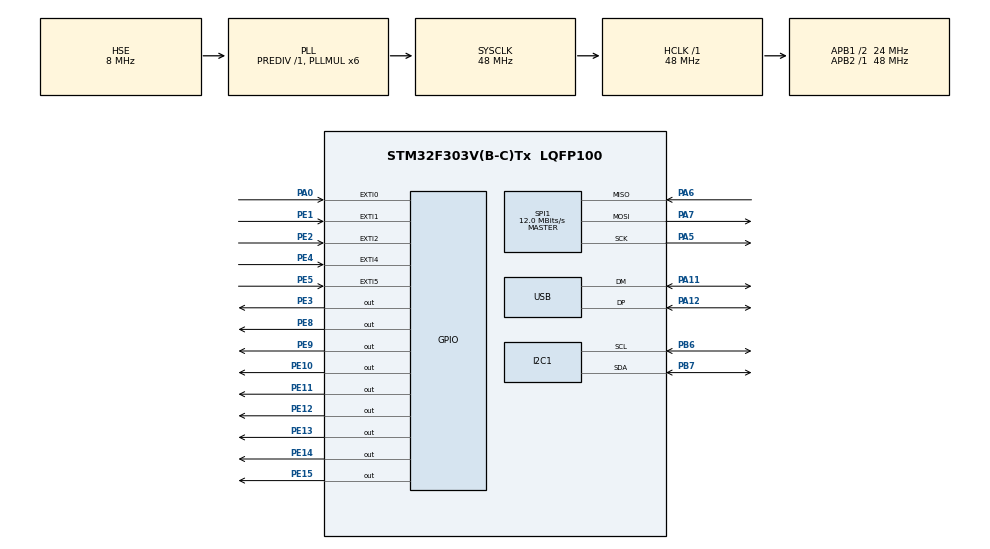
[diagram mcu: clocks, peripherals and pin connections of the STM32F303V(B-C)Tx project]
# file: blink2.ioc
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FREERTOS.Tasks01=defaultTask,0,128,StartDefaultTask,Default
FREERTOS.configTOTAL_HEAP_SIZE=4096
I2C1.Timing-I2C=0x2000090E
Mcu.Family=STM32F3
Mcu.Name=STM32F303V(B-C)Tx
Mcu.Package=LQFP100
NVIC.EXTI0_IRQn=true\:5\:0\:false\:false\:true\:true
NVIC.PriorityGroup=NVIC_PRIORITYGROUP_4
PA0.GPIO_ModeDefaultEXTI=GPIO_MODE_IT_RISING
PA0.GPIO_PuPd=GPIO_NOPULL
PA0.Signal=GPXTI0
PA11.GPIO_Mode=GPIO_MODE_AF_PP
PA11.GPIO_PuPd=GPIO_NOPULL
PA11.GPIO_Speed=GPIO_SPEED_FREQ_HIGH
PA11.Mode=Device
PA11.Signal=USB_DM
PA12.GPIO_Mode=GPIO_MODE_AF_PP
PA12.GPIO_PuPd=GPIO_NOPULL
PA12.GPIO_Speed=GPIO_SPEED_FREQ_HIGH
PA12.Mode=Device
PA12.Signal=USB_DP
PA13.Mode=Serial_Wire
PA13.Signal=SYS_JTMS-SWDIO
PA14.Mode=Serial_Wire
PA14.Signal=SYS_JTCK-SWCLK
PA5.GPIO_Mode=GPIO_MODE_AF_PP
PA5.GPIO_PuPd=GPIO_NOPULL
PA5.GPIO_Speed=GPIO_SPEED_FREQ_HIGH
PA5.Mode=Full_Duplex_Master
PA5.Signal=SPI1_SCK
PA6.GPIO_Mode=GPIO_MODE_AF_PP
PA6.GPIO_PuPd=GPIO_NOPULL
PA6.GPIO_Speed=GPIO_SPEED_FREQ_HIGH
PA6.Mode=Full_Duplex_Master
PA6.Signal=SPI1_MISO
PA7.GPIO_Mode=GPIO_MODE_AF_PP
PA7.GPIO_PuPd=GPIO_NOPULL
PA7.GPIO_Speed=GPIO_SPEED_FREQ_HIGH
PA7.Mode=Full_Duplex_Master
PA7.Signal=SPI1_MOSI
PB3.Signal=SYS_JTDO-TRACESWO
PB6.GPIO_FM6=__NULL
PB6.GPIO_Mode=GPIO_MODE_AF_OD
PB6.GPIO_PuPdOD=GPIO_PULLUP
PB6.GPIO_Speed=GPIO_SPEED_FREQ_HIGH
PB6.Mode=I2C
PB6.Signal=I2C1_SCL
PB7.GPIO_FM7=__NULL
PB7.GPIO_Mode=GPIO_MODE_AF_OD
PB7.GPIO_PuPdOD=GPIO_PULLUP
PB7.GPIO_Speed=GPIO_SPEED_FREQ_HIGH
PB7.Mode=I2C
PB7.Signal=I2C1_SDA
PC14-OSC32_IN.Signal=RCC_OSC32_IN
PC15-OSC32_OUT.Signal=RCC_OSC32_OUT
PE1.GPIO_ModeDefaultEXTI=GPIO_MODE_IT_RISING
PE1.GPIO_PuPd=GPIO_NOPULL
PE1.Signal=GPXTI1
PE10.GPIO_ModeDefaultOutputPP=GPIO_MODE_OUTPUT_PP
PE10.GPIO_PuPd=GPIO_NOPULL
PE10.GPIO_Speed=GPIO_SPEED_FREQ_LOW
PE10.PinState=GPIO_PIN_RESET
PE10.Signal=GPIO_Output
PE11.GPIO_ModeDefaultOutputPP=GPIO_MODE_OUTPUT_PP
PE11.GPIO_PuPd=GPIO_NOPULL
PE11.GPIO_Speed=GPIO_SPEED_FREQ_LOW
PE11.PinState=GPIO_PIN_RESET
PE11.Signal=GPIO_Output
PE12.GPIO_ModeDefaultOutputPP=GPIO_MODE_OUTPUT_PP
PE12.GPIO_PuPd=GPIO_NOPULL
PE12.GPIO_Speed=GPIO_SPEED_FREQ_LOW
PE12.PinState=GPIO_PIN_RESET
PE12.Signal=GPIO_Output
PE13.GPIO_ModeDefaultOutputPP=GPIO_MODE_OUTPUT_PP
PE13.GPIO_PuPd=GPIO_NOPULL
PE13.GPIO_Speed=GPIO_SPEED_FREQ_LOW
PE13.PinState=GPIO_PIN_RESET
PE13.Signal=GPIO_Output
PE14.GPIO_ModeDefaultOutputPP=GPIO_MODE_OUTPUT_PP
PE14.GPIO_PuPd=GPIO_NOPULL
PE14.GPIO_Speed=GPIO_SPEED_FREQ_LOW
PE14.PinState=GPIO_PIN_RESET
PE14.Signal=GPIO_Output
PE15.GPIO_ModeDefaultOutputPP=GPIO_MODE_OUTPUT_PP
PE15.GPIO_PuPd=GPIO_NOPULL
PE15.GPIO_Speed=GPIO_SPEED_FREQ_LOW
PE15.PinState=GPIO_PIN_RESET
PE15.Signal=GPIO_Output
PE2.GPIO_ModeDefaultEXTI=GPIO_MODE_IT_RISING
PE2.GPIO_PuPd=GPIO_NOPULL
PE2.Signal=GPXTI2
PE3.GPIO_ModeDefaultOutputPP=GPIO_MODE_OUTPUT_PP
PE3.GPIO_PuPd=GPIO_NOPULL
PE3.GPIO_Speed=GPIO_SPEED_FREQ_LOW
PE3.PinState=GPIO_PIN_RESET
PE3.Signal=GPIO_Output
PE4.GPIO_ModeDefaultEXTI=GPIO_MODE_IT_RISING
PE4.GPIO_PuPd=GPIO_NOPULL
PE4.Signal=GPXTI4
PE5.GPIO_ModeDefaultEXTI=GPIO_MODE_IT_RISING
PE5.GPIO_PuPd=GPIO_NOPULL
PE5.Signal=GPXTI5
PE8.GPIO_ModeDefaultOutputPP=GPIO_MODE_OUTPUT_PP
PE8.GPIO_PuPd=GPIO_NOPULL
PE8.GPIO_Speed=GPIO_SPEED_FREQ_LOW
PE8.PinState=GPIO_PIN_RESET
PE8.Signal=GPIO_Output
PE9.GPIO_ModeDefaultOutputPP=GPIO_MODE_OUTPUT_PP
PE9.GPIO_PuPd=GPIO_NOPULL
PE9.GPIO_Speed=GPIO_SPEED_FREQ_LOW
PE9.PinState=GPIO_PIN_RESET
PE9.Signal=GPIO_Output
PF0-OSC_IN.Mode=HSE-External-Clock-Source
PF0-OSC_IN.Signal=RCC_OSC_IN
PF1-OSC_OUT.Signal=RCC_OSC_OUT
ProjectManager.HeapSize=0x0
ProjectManager.StackSize=0x0
ProjectManager.TargetToolchain=TrueSTUDIO
RCC.AHBFreq_Value=48000000
RCC.APB1CLKDivider=RCC_HCLK_DIV2
RCC.APB1Freq_Value=24000000
RCC.APB1TimFreq_Value=48000000
RCC.APB2Freq_Value=48000000
RCC.APB2TimFreq_Value=48000000
RCC.CortexFreq_Value=48000000
RCC.HCLKFreq_Value=48000000
RCC.HSEUsed=1
RCC.HSE_VALUE=8000000
RCC.HSI_VALUE=8000000
RCC.LSE_VALUE=32768
RCC.PLLMUL=RCC_PLL_MUL6
RCC.PLLSourceARG=RCC_PLLSOURCE_HSE
RCC.SYSCLKFreq_VALUE=48000000
RCC.SYSCLKSourceVirtual=RCC_SYSCLKSOURCE_PLLCLK
RCC.USBFreq_Value=48000000
SPI1.BaudRatePrescaler=SPI_BAUDRATEPRESCALER_4
SPI1.CalculateBaudRate=12.0 MBits/s
SPI1.Mode=SPI_MODE_MASTER
VP_FREERTOS_VS_ENABLE.Mode=Enabled
board=STM32F3DISCOVERY

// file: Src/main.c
/**
  ******************************************************************************
  * File Name          : main.c
  * Description        : Main program body
  ******************************************************************************
  *
  * Copyright (c) 2016 STMicroelectronics International N.V.
  * All rights reserved.
  *
  * Redistribution and use in source and binary forms, with or without
  * modification, are permitted, provided that the following conditions are met:
  *
  * 1. Redistribution of source code must retain the above copyright notice,
  *    this list of conditions and the following disclaimer.
  * 2. Redistributions in binary form must reproduce the above copyright notice,
  *    this list of conditions and the following disclaimer in the documentation
  *    and/or other materials provided with the distribution.
  * 3. Neither the name of STMicroelectronics nor the names of other
  *    contributors to this software may be used to endorse or promote products
  *    derived from this software without specific written permission.
  * 4. This software, including modifications and/or derivative works of this
  *    software, must execute solely and exclusively on microcontroller or
  *    microprocessor devices manufactured by or for STMicroelectronics.
  * 5. Redistribution and use of this software other than as permitted under
  *    this license is void and will automatically terminate your rights under
  *    this license.
  *
  * THIS SOFTWARE IS PROVIDED BY STMICROELECTRONICS AND CONTRIBUTORS "AS IS"
  * AND ANY EXPRESS, IMPLIED OR STATUTORY WARRANTIES, INCLUDING, BUT NOT
  * LIMITED TO, THE IMPLIED WARRANTIES OF MERCHANTABILITY, FITNESS FOR A
  * PARTICULAR PURPOSE AND NON-INFRINGEMENT OF THIRD PARTY INTELLECTUAL PROPERTY
  * RIGHTS ARE DISCLAIMED TO THE FULLEST EXTENT PERMITTED BY LAW. IN NO EVENT
  * SHALL STMICROELECTRONICS OR CONTRIBUTORS BE LIABLE FOR ANY DIRECT, INDIRECT,
  * INCIDENTAL, SPECIAL, EXEMPLARY, OR CONSEQUENTIAL DAMAGES (INCLUDING, BUT NOT
  * LIMITED TO, PROCUREMENT OF SUBSTITUTE GOODS OR SERVICES; LOSS OF USE, DATA,
  * OR PROFITS; OR BUSINESS INTERRUPTION) HOWEVER CAUSED AND ON ANY THEORY OF
  * LIABILITY, WHETHER IN CONTRACT, STRICT LIABILITY, OR TORT (INCLUDING
  * NEGLIGENCE OR OTHERWISE) ARISING IN ANY WAY OUT OF THE USE OF THIS SOFTWARE,
  * EVEN IF ADVISED OF THE POSSIBILITY OF SUCH DAMAGE.
  *
  ******************************************************************************
  */
#include "main.h"
#include "stm32f3xx_hal.h"
#include "cmsis_os.h"
#include "i2c.h"
#include "spi.h"
#include "usb.h"
#include "gpio.h"

/* USER CODE BEGIN PV */
/* Private variables ---------------------------------------------------------*/

/* USER CODE END PV */

void SystemClock_Config(void);
void Error_Handler(void);
void MX_FREERTOS_Init(void);

/* USER CODE BEGIN PFP */
/* Private function prototypes -----------------------------------------------*/

/* USER CODE END PFP */

int main(void)
{

  /* MCU Configuration----------------------------------------------------------*/

  /* Reset of all peripherals, Initializes the Flash interface and the Systick. */
  HAL_Init();

  /* Configure the system clock */
  SystemClock_Config();

  /* Initialize all configured peripherals */
  MX_GPIO_Init();
  MX_I2C1_Init();
  MX_SPI1_Init();
  MX_USB_PCD_Init();

  /* Call init function for freertos objects (in freertos.c) */
  MX_FREERTOS_Init();

  /* Start scheduler */
  osKernelStart();

  /* We should never get here as control is now taken by the scheduler */

  /* Infinite loop */
  while (1)
  {

  }

}

/** System Clock Configuration
*/
void SystemClock_Config(void)
{

  RCC_OscInitTypeDef RCC_OscInitStruct;
  RCC_ClkInitTypeDef RCC_ClkInitStruct;
  RCC_PeriphCLKInitTypeDef PeriphClkInit;

    /**Initializes the CPU, AHB and APB busses clocks
    */
  RCC_OscInitStruct.OscillatorType = RCC_OSCILLATORTYPE_HSI|RCC_OSCILLATORTYPE_HSE;
  RCC_OscInitStruct.HSEState = RCC_HSE_BYPASS;
  RCC_OscInitStruct.HSEPredivValue = RCC_HSE_PREDIV_DIV1;
  RCC_OscInitStruct.HSIState = RCC_HSI_ON;
  RCC_OscInitStruct.HSICalibrationValue = 16;
  RCC_OscInitStruct.PLL.PLLState = RCC_PLL_ON;
  RCC_OscInitStruct.PLL.PLLSource = RCC_PLLSOURCE_HSE;
  RCC_OscInitStruct.PLL.PLLMUL = RCC_PLL_MUL6;
  if (HAL_RCC_OscConfig(&RCC_OscInitStruct) != HAL_OK)
  {
    Error_Handler();
  }

    /**Initializes the CPU, AHB and APB busses clocks
    */
  RCC_ClkInitStruct.ClockType = RCC_CLOCKTYPE_HCLK|RCC_CLOCKTYPE_SYSCLK
                              |RCC_CLOCKTYPE_PCLK1|RCC_CLOCKTYPE_PCLK2;
  RCC_ClkInitStruct.SYSCLKSource = RCC_SYSCLKSOURCE_PLLCLK;
  RCC_ClkInitStruct.AHBCLKDivider = RCC_SYSCLK_DIV1;
  RCC_ClkInitStruct.APB1CLKDivider = RCC_HCLK_DIV2;
  RCC_ClkInitStruct.APB2CLKDivider = RCC_HCLK_DIV1;

  if (HAL_RCC_ClockConfig(&RCC_ClkInitStruct, FLASH_LATENCY_1) != HAL_OK)
  {
    Error_Handler();
  }

  PeriphClkInit.PeriphClockSelection = RCC_PERIPHCLK_USB|RCC_PERIPHCLK_I2C1;
  PeriphClkInit.I2c1ClockSelection = RCC_I2C1CLKSOURCE_HSI;
  PeriphClkInit.USBClockSelection = RCC_USBCLKSOURCE_PLL;
  if (HAL_RCCEx_PeriphCLKConfig(&PeriphClkInit) != HAL_OK)
  {
    Error_Handler();
  }

    /**Configure the Systick interrupt time
    */
  HAL_SYSTICK_Config(HAL_RCC_GetHCLKFreq()/1000);

    /**Configure the Systick
    */
  HAL_SYSTICK_CLKSourceConfig(SYSTICK_CLKSOURCE_HCLK);

  /* SysTick_IRQn interrupt configuration */
  HAL_NVIC_SetPriority(SysTick_IRQn, 15, 0);
}

void Error_Handler(void)
{
  while(1)
  {
  }
}

/************************ (C) COPYRIGHT STMicroelectronics *****END OF FILE****/

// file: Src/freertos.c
/**
  ******************************************************************************
  * File Name          : freertos.c
  * Description        : Code for freertos applications
  ******************************************************************************
  *
  * Copyright (c) 2016 STMicroelectronics International N.V.
  * All rights reserved.
  *
  * Redistribution and use in source and binary forms, with or without
  * modification, are permitted, provided that the following conditions are met:
  *
  * 1. Redistribution of source code must retain the above copyright notice,
  *    this list of conditions and the following disclaimer.
  * 2. Redistributions in binary form must reproduce the above copyright notice,
  *    this list of conditions and the following disclaimer in the documentation
  *    and/or other materials provided with the distribution.
  * 3. Neither the name of STMicroelectronics nor the names of other
  *    contributors to this software may be used to endorse or promote products
  *    derived from this software without specific written permission.
  * 4. This software, including modifications and/or derivative works of this
  *    software, must execute solely and exclusively on microcontroller or
  *    microprocessor devices manufactured by or for STMicroelectronics.
  * 5. Redistribution and use of this software other than as permitted under
  *    this license is void and will automatically terminate your rights under
  *    this license.
  *
  * THIS SOFTWARE IS PROVIDED BY STMICROELECTRONICS AND CONTRIBUTORS "AS IS"
  * AND ANY EXPRESS, IMPLIED OR STATUTORY WARRANTIES, INCLUDING, BUT NOT
  * LIMITED TO, THE IMPLIED WARRANTIES OF MERCHANTABILITY, FITNESS FOR A
  * PARTICULAR PURPOSE AND NON-INFRINGEMENT OF THIRD PARTY INTELLECTUAL PROPERTY
  * RIGHTS ARE DISCLAIMED TO THE FULLEST EXTENT PERMITTED BY LAW. IN NO EVENT
  * SHALL STMICROELECTRONICS OR CONTRIBUTORS BE LIABLE FOR ANY DIRECT, INDIRECT,
  * INCIDENTAL, SPECIAL, EXEMPLARY, OR CONSEQUENTIAL DAMAGES (INCLUDING, BUT NOT
  * LIMITED TO, PROCUREMENT OF SUBSTITUTE GOODS OR SERVICES; LOSS OF USE, DATA,
  * OR PROFITS; OR BUSINESS INTERRUPTION) HOWEVER CAUSED AND ON ANY THEORY OF
  * LIABILITY, WHETHER IN CONTRACT, STRICT LIABILITY, OR TORT (INCLUDING
  * NEGLIGENCE OR OTHERWISE) ARISING IN ANY WAY OUT OF THE USE OF THIS SOFTWARE,
  * EVEN IF ADVISED OF THE POSSIBILITY OF SUCH DAMAGE.
  *
  ******************************************************************************
  */

#include "FreeRTOS.h"
#include "cmsis_os.h"
#include "task.h"

osThreadId defaultTaskHandle;

void StartDefaultTask(void const *argument);

void MX_FREERTOS_Init(void); /* (MISRA C 2004 rule 8.1) */

/* USER CODE BEGIN FunctionPrototypes */
extern void App_createStatic();
/* USER CODE END FunctionPrototypes */

/* Hook prototypes */

/* Init FreeRTOS */

void MX_FREERTOS_Init(void) {
    /* USER CODE BEGIN Init */
    App_createStatic();
    /* USER CODE END Init */

    /* Create the thread(s) */
    /* definition and creation of defaultTask */
    osThreadDef(defaultTask, StartDefaultTask, osPriorityNormal, 0, 128);
    defaultTaskHandle = osThreadCreate(osThread(defaultTask), NULL);

}

/* StartDefaultTask function */
void StartDefaultTask(void const *argument) {

    for (;;) {
        osDelay(1);
    }
}

/************************ (C) COPYRIGHT STMicroelectronics *****END OF FILE****/
